# M460_v1 register map
File version: 1.0
Registers are 32-bit, read-write, reset 0x0 unless marked. A register's access mark holds for its fields unless they carry their own. Offsets are from the block's base; [hi:lo] are bit positions.

## HBI — HBI Register Map
Base 0x400CE000
0x00 HBI_CMD — HyperBus Command and Status Register
  [3:0] HYPCMD — HyperBus Command and Status. Write. Note: When an operation is Done, the read value automatically return to 4'b0000.
    0=HyperBus interface is Idle; 1=Reset HyperRAM; 2=Read HyperRAM register (16-Bit, Read Data[15:0]; 5=Exit From Hybrid Sleep and deep power down; 7=Write HyperRAM register (16-Bit, Write Data[15:0]; 8=Read 1 word (Read Data[15:0]) from HyperRAM; 9=Read 2 words (Read Data[31:0]) from HyperRAM; 12=Write 1 Byte (Write Data[7:0]) to HyperRAM; 13=Write 2 Bytes (Write Data[15:0]) to HyperRAM; 14=Write 3 Bytes (Write Data[23:0]) to HyperRAM; 15=Write 4 Bytes (Write Data[31:0]) to HyperRAM
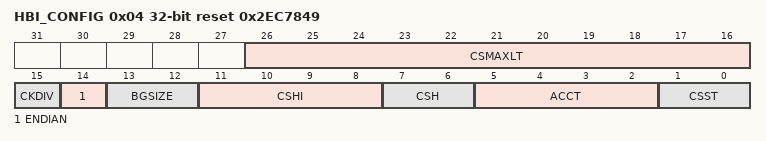
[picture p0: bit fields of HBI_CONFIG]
0x04 HBI_CONFIG reset 0x2EC7849 — HyperBus Configuration Register
  [26:16] CSMAXLT — Chip Select Maximum Low Time. This field indicates the maximum Low period of the chip select (CS#) in one transaction. Note: This field indicates the timing of HyperRAM Chip Select specification so that it has to relative the frequency of HCLK and the CLKDIV (HBI_CONFIG[15]).
    0=1 HCLK cycle; 1=2 HCLK cycles; 2=3 HCLK cycles; 3=4 HCLK cycles; 0x2EC=749 HCLK cycles (3.9us @192 MHz); 0x7FE=2047 HCLK cycles; 0x7FF=2048 HCLK cycles
  [15] CKDIV — Hyper Bus Clock Divider
    0=Hyper Bus Clock rate is HCLK/2; 1=Hyper Bus Clock rate is HCLK/4
  [14] ENDIAN — Endian Condition on the Hyper Bus Data Pipe
    0=Little-Endian; 1=Big-Endian
  [13:12] BGSIZE — Burst Group Size. This field indicates the burst length on the Hyper Bus transaction. Note: This field must be set to the same value as 'Burst Length' in HyperRAM's Configuration Register 0.
    0=128 Bytes; 1=64 Bytes; 2=16 Bytes; 3=32 Bytes
  [11:8] CSHI — Chip Select High between Transaction. This field indicates the inactive period between two Hyper Bus transactions. Note: This field must meet the HyperRAM device's specification of tCSHI.
    0=1 HCLK cycle; 1=2 HCLK cycles; 2=3 HCLK cycles; 3=4 HCLK cycles; 15=16 HCLK cycles
  [7:6] CSH — Chip Select Hold Time After CK Falling Edge. This field indicates the hold time between the last CK falling edge and chip select
    0=0.5 HCLK cycles; 1=1.5 HCLK cycles; 2=2.5 HCLK cycles; 3=3.5 HCLK cycles
  [5:2] ACCT — Initial Access Time. This field indicates the initial access cycles of the Hyper Bus transaction. Note: This field must be set to the same value as 'Initial Latency' in HyperRAM's Configuration Register 0.
    0=5 CK cycles; 1=6 CK cycles; 2=7 CK cycles; 14=3 CK cycles; 15=4 CK cycles
  [1:0] CSST — Chip Select Setup Time to Next CK Rising Edge. This field indicates the setup time between the chip select and the next CK rising edge
    0=1.5 HCLK cycles; 1=2.5 HCLK cycles; 2=3.5 HCLK cycles; 3=4.5 HCLK cycles
0x08 HBI_ADR — HyperBus Byte Address access Register
  [31:0] ADR — HyperBus Byte Address. Memory Space Range: 0x0000_0000 ~ 0x01FF_FFFF. Register Space Range: Note: It is 'Byte' address, not 'word' address. Up to 32M Bytes of memory space is supported.
0x0C HBI_WDATA — HyperBus 32-Bits Write Data Register
  [31:0] WDATA — HyperBus 32-Bits Write Data. To write 1 Byte to HyperRAM, Byte 0 (Data[7:0]) is used. To write 2 Bytes to HyperRAM, Byte 1~0 (Data[15:0]) is used. To write 3 Bytes to HyperRAM, Byte 2~0 (Data[23:0]) is used. To write 4 Bytes to HyperRAM, Byte 3~0 (Data[31:0]) is used
0x10 HBI_RDATA — HyperBus 32-Bits Read Data Register
  [31:0] RDATA — HyperBus 32-Bits Read Data. 32-Bits Data for HyperBus Read. Note: The data order depends on the ENDIAN (HBI_CONFIG[14]). Refer to Memory and Data Map section for detailed information.
0x14 HBI_INTEN — HyperBus Interrupt Enable Register
  [0] OPINTEN — HyperBus Operation Done Interrupt Enable
    0=Operation done interrupt Disabled; 1=Operation done interrupt Enabled
0x18 HBI_INTSTS — HyperBus Interrupt Status Register
  [0] OPDONE — HyperBus Operation Done Interrupt
    0=HyperBus operation is busy; 1=HyperBus operation is done
